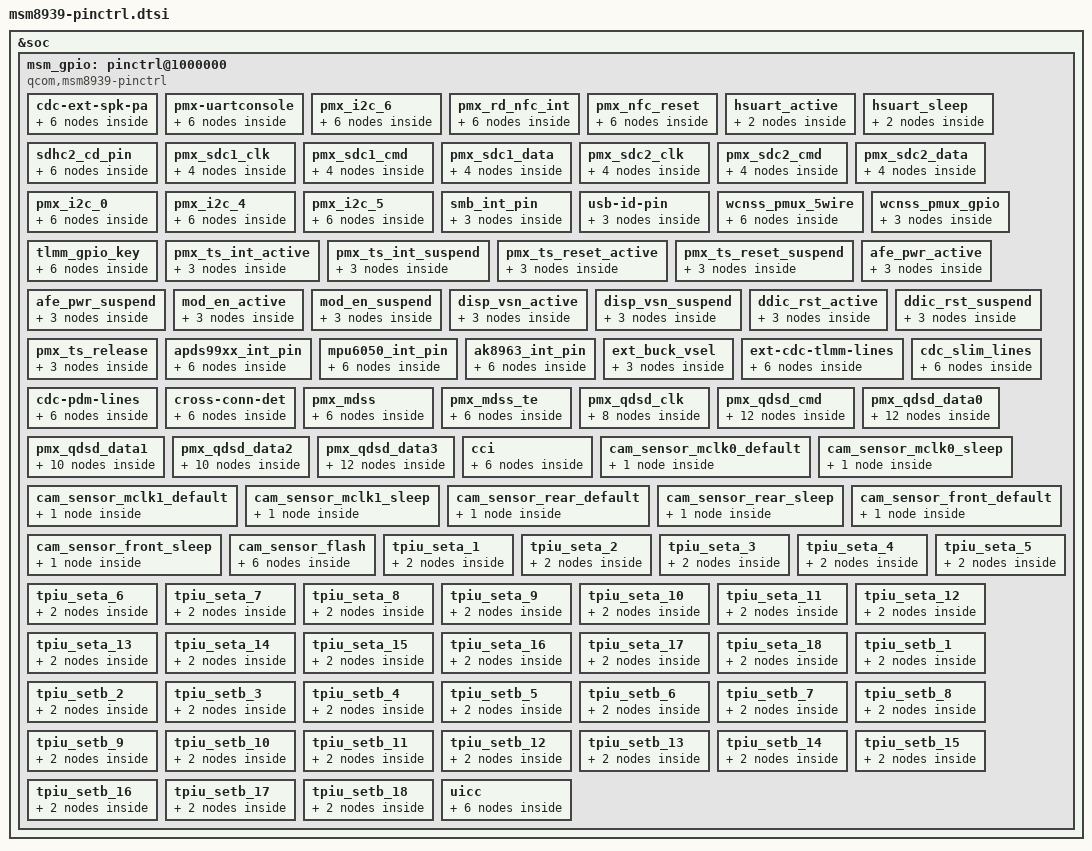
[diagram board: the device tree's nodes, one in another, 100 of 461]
/* Copyright (c) 2014-2015, The Linux Foundation. All rights reserved.
 * Copyright (c) 2018, Pavel Dubrova <pashadubrova@gmail.com
 *
 * This program is free software; you can redistribute it and/or modify
 * it under the terms of the GNU General Public License version 2 and
 * only version 2 as published by the Free Software Foundation.
 *
 * This program is distributed in the hope that it will be useful,
 * but WITHOUT ANY WARRANTY; without even the implied warranty of
 * MERCHANTABILITY or FITNESS FOR A PARTICULAR PURPOSE.  See the
 * GNU General Public License for more details.
 */

&soc {
	msm_gpio: pinctrl@1000000 {
		compatible = "qcom,msm8939-pinctrl";
		reg = <0x1000000 0x300000>;
		interrupts = <0 208 0>;
		gpio-controller;
		#gpio-cells = <2>;
		interrupt-controller;
		#interrupt-cells = <2>;

		cdc-ext-spk-pa {
			cdc_ext_spk_pa_active: cdc_ext_spk_pa_on {
				mux {
					pins = "gpio0";
					function = "gpio";
				};

				config {
					pins = "gpio0";
					drive-strength = <8>;
					output-low;
					bias-pull-none;
				};
			};

			cdc_ext_spk_pa_sus: cdc_ext_spk_pa_off {
				mux {
					pins = "gpio0";
					function = "gpio";
				};

				config {
					pins = "gpio0";
					drive-strength = <2>;
					bias-disable;
				};
			};
		};

		pmx-uartconsole {
			uart_console_active: uart_console_active {
				mux {
					pins = "gpio4", "gpio5";
					function = "gpio";
				};

				config {
					pins = "gpio4", "gpio5";
					drive-strength = <2>;
					bias-disable;
				};
			};

			uart_console_sleep: uart_console_sleep {
				mux {
					pins = "gpio4", "gpio5";
					function = "blsp_uart2";
				};

				config {
					pins = "gpio4", "gpio5";
					drive-strength = <2>;
					bias-pull-down;
				};
			};
		};

		pmx_i2c_6 {
			/* active state */
			i2c_6_active: i2c_6_active {
				mux {
					/* CLK, DATA */
					pins = "gpio22", "gpio23";
					function = "blsp_i2c6";
				};

				config {
					pins = "gpio22", "gpio23";
					drive-strength = <2>; /* 2 MA */
					bias-disable; /* No PULL */
				};
			};

			/* suspended state */
			i2c_6_sleep: i2c_6_sleep {
				mux {
					/* CLK, DATA */
					pins = "gpio22", "gpio23";
					function = "blsp_i2c6";
				};

				config {
					pins = "gpio22", "gpio23";
					drive-strength = <2>; /* 2 MA */
					bias-disable; /* No PULL */
				};
			};
		};

		pmx_rd_nfc_int {
			nfc_int_active: nfc_int_active {
				mux {
					pins = "gpio21";
					function = "gpio";
				};

				config {
					pins = "gpio21";
					drive-strength = <6>;
					bias-pull-up;
				};
			};

			nfc_int_suspend: nfc_int_suspend {
				mux {
					pins = "gpio21";
					function = "gpio";
				};

				config {
					pins = "gpio21";
					drive-strength = <6>;
					bias-pull-up;
				};
			};
		};

		pmx_nfc_reset {
			nfc_disable_active: nfc_disable_active {
				mux {
					pins = "gpio20";
					function = "gpio";
				};

				config {
					pins = "gpio20";
					drive-strength = <6>;
					bias-pull-up;
				};
			};

			nfc_disable_suspend: nfc_disable_suspend {
				mux {
					pins = "gpio20";
					function = "gpio";
				};

				config {
					pins = "gpio20";
					drive-strength = <6>;
					bias-disable;
				};
			};
		};

		hsuart_active: hsuart_active {
			mux {
				pins = "gpio0", "gpio1", "gpio2", "gpio3";
				function = "blsp_uart1";
			};

			config {
				pins = "gpio0", "gpio1", "gpio2", "gpio3";
				drive-strength = <16>;
				bias-disable;
			};
		};

		hsuart_sleep: hsuart_sleep {
			mux {
				pins = "gpio0", "gpio1", "gpio2", "gpio3";
				function = "blsp_uart1";
			};

			config {
				pins = "gpio0", "gpio1", "gpio2", "gpio3";
				drive-strength = <2>;
				bias-disable;
			};
		};

		sdhc2_cd_pin {
			sdc2_cd_on: cd_on {
				mux {
					pins = "gpio38";
					function = "gpio";
				};

				config {
					pins = "gpio38";
					drive-strength = <2>;
					bias-pull-up;
				};
			};

			sdc2_cd_off: cd_off {
				mux {
					pins = "gpio38";
					function = "gpio";
				};

				config {
					pins = "gpio38";
					drive-strength = <2>;
					bias-disable;
				};
			};
		};

		pmx_sdc1_clk {
			sdc1_clk_on: clk_on {
				config {
					pins = "sdc1_clk";
					bias-disable; /* NO pull */
					drive-strength = <16>; /* 16 MA */
				};
			};

			sdc1_clk_off: clk_off {
				config {
					pins = "sdc1_clk";
					bias-disable; /* NO pull */
					drive-strength = <2>; /* 2 MA */
				};
			};
		};

		pmx_sdc1_cmd {
			sdc1_cmd_on: cmd_on {
				config {
					pins = "sdc1_cmd";
					bias-pull-up; /* pull up */
					drive-strength = <10>; /* 10 MA */
				};
			};

			sdc1_cmd_off: cmd_off {
				config {
					pins = "sdc1_cmd";
					bias-pull-up; /* pull up */
					drive-strength = <2>; /* 2 MA */
				};
			};
		};

		pmx_sdc1_data {
			sdc1_data_on: data_on {
				config {
					pins = "sdc1_data";
					bias-pull-up; /* pull up */
					drive-strength = <10>; /* 10 MA */
				};
			};

			sdc1_data_off: data_off {
				config {
					pins = "sdc1_data";
					bias-pull-up; /* pull up */
					drive-strength = <2>; /* 2 MA */
				};
			};
		};

		pmx_sdc2_clk {
			sdc2_clk_on: clk_on {
				config {
					pins = "sdc2_clk";
					bias-disable; /* NO pull */
					drive-strength = <16>; /* 16 MA */
				};
			};

			sdc2_clk_off: clk_off {
				config {
					pins = "sdc2_clk";
					bias-disable; /* NO pull */
					drive-strength = <2>; /* 2 MA */
				};
			};
		};

		pmx_sdc2_cmd {
			sdc2_cmd_on: cmd_on {
				config {
					pins = "sdc2_cmd";
					bias-pull-up; /* pull up */
					drive-strength = <10>; /* 10 MA */
				};
			};

			sdc2_cmd_off: cmd_off {
				config {
					pins = "sdc2_cmd";
					bias-pull-up; /* pull up */
					drive-strength = <2>; /* 2 MA */
				};
			};
		};

		pmx_sdc2_data {
			sdc2_data_on: data_on {
				config {
					pins = "sdc2_data";
					bias-pull-up; /* pull up */
					drive-strength = <10>; /* 10 MA */
				};
			};

			sdc2_data_off: data_off {
				config {
					pins = "sdc2_data";
					bias-pull-up; /* pull up */
					drive-strength = <2>; /* 2 MA */
				};
			};
		};

		pmx_i2c_0 {
			i2c_0_active: i2c_0_active {
				mux {
					pins = "gpio6", "gpio7";
					function = "blsp_i2c2";
				};

				config {
					pins = "gpio6", "gpio7";
					drive-strength = <2>; /* 2 MA */
					bias-disable;         /* No PULL */
				};
			};

			i2c_0_sleep: i2c_0_sleep {
				mux {
					pins = "gpio6", "gpio7";
					function = "blsp_i2c2";
				};

				config {
					pins = "gpio6", "gpio7";
					drive-strength = <2>; /* 2 MA */
					bias-disable;	      /* No PULL */
				};
			};
		};

		pmx_i2c_4 {
			i2c_4_active: i2c_4_active {
				mux {
					pins = "gpio14", "gpio15";
					function = "blsp_i2c4";
				};

				config {
					pins = "gpio14", "gpio15";
					drive-strength = <2>; /* 2 MA */
					bias-disable;         /* No PULL */
				};
			};

			i2c_4_sleep: i2c_4_sleep {
				mux {
					pins = "gpio14", "gpio15";
					function = "blsp_i2c4";
				};

				config {
					pins = "gpio14", "gpio15";
					drive-strength = <2>; /* 2 MA */
					bias-disable;	      /* No PULL */
				};
			};
		};

		pmx_i2c_5 {
			i2c_5_active: i2c_5_active {
				mux {
					pins = "gpio18", "gpio19";
					function = "blsp_i2c5";
				};

				config {
					pins = "gpio18", "gpio19";
					drive-strength = <2>; /* 2 MA */
					bias-disable;         /* No PULL */
				};
			};

			i2c_5_sleep: i2c_5_sleep {
				mux {
					pins = "gpio18", "gpio19";
					function = "blsp_i2c5";
				};

				config {
					pins = "gpio18", "gpio19";
					drive-strength = <2>; /* 2 MA */
					bias-disable;	      /* No PULL */
				};
			};
		};

		smb_int_pin {
			smb_int_default: smb_int_default {
				mux {
					pins = "gpio62";
					function = "gpio";
				};

				config {
					pins = "gpio62";
					drive-strength = <2>;	/* 2 MA */
					bias-pull-up;		/* PULL UP*/
				};
			};
		};

		usb-id-pin {
			usbid_default: default {
				mux {
					pins = "gpio110";
					function = "gpio";
				};

				config {
					pins = "gpio110";
					drive-strength = <8>;
					bias-pull-up;
				};
			};
		};

#if 0
		 spi0_active {
                        /* MOSI, MISO, CLK */
                        qcom,pins = <&gp 8>, <&gp 9>, <&gp 11>;
                        qcom,num-grp-pins = <3>;
                        qcom,pin-func = <1>;
                        label = "spi0-active";
                        /* active state */
                        spi0_default: spi0_default {
                             wcnss_pmux_5wire   drive-strength = <12>; /* 12 MA */
                                bias-disable = <0>; /* No PULL */
                        };
                };

                spi0_suspend {
                        /* MOSI, MISO, CLK */
                        qcom,pins = <&gp 8>, <&gp 9>, <&gp 11>;
                        qcom,num-grp-pins = <3>;
                        qcom,pin-func = <0>;
                        label = "spi0-suspend";
                        /* suspended state */
                        spi0_sleep: spi0_sleep {
                                drive-strength = <2>; /* 2 MA */
			        bias-pull-down; /* PULL Down */
                        };
                };

                spi0_cs0_active {
                        /* CS */
                        qcom,pins = <&gp 10>;
                        qcom,num-grp-pins = <1>;
                        qcom,pin-func = <1>;
                        label = "spi0-cs0-active";
                        spi0_cs0_active: cs0_active {
                                drive-strength = <2>;
                                bias-disable = <0>;
                        };
                };

                spi0_cs0_suspend {
                        /* CS */
                        qcom,pins = <&gp 10>;
                        qcom,num-grp-pins = <1>;
                        qcom,pin-func = <0>;
                        label = "spi0-cs0-suspend";
                        spi0_cs0_sleep: cs0_sleep {
                                drive-strength = <2>;
                                bias-disable = <0>;
                        };
                };

		spi5_active {
                        /* MOSI, MISO, CLK */
                        qcom,pins = <&gp 16>, <&gp 17>, <&gp 19>;
                        qcom,num-grp-pins = <3>;
                        qcom,pin-func = <1>;
                        label = "spi5-active";
                        /* active state */
                        spi5_default: spi5_default {
                                drive-strength = <16>; /* 16 MA */
                                bias-disable = <0>; /* No PULL */
                        };
                };

                spi5_suspend {
                        /* MOSI, MISO, CLK */
                        qcom,pins = <&gp 16>, <&gp 17>, <&gp 19>;
                        qcom,num-grp-pins = <3>;
                        qcom,pin-func = <0>;
                        label = "spi5-suspend";
                        /* suspended state */
                        spi5_sleep: spi5_sleep {
                                drive-strength = <2>; /* 2 MA */
                                bias-disable = <0>; /* No PULL */
                        };
                };

                spi5_cs0_active {
                        /* CS */
                        qcom,pins = <&gp 18>;
                        qcom,num-grp-pins = <1>;
                        qcom,pin-func = <1>;
                        label = "spi5-cs0-active";
                        spi5_cs0_active: cs0_active {
                                drive-strength = <2>;
                                bias-disable = <0>;
                        };
                };

                spi5_cs0_suspend {
                        /* CS */
                        qcom,pins = <&gp 18>;
                        qcom,num-grp-pins = <1>;
                        qcom,pin-func = <0>;
                        label = "spi5-cs0-suspend";
                        spi5_cs0_sleep: cs0_sleep {
                                drive-strength = <2>;
                                bias-disable = <0>;
                        };
                };
#endif

		wcnss_pmux_5wire {
			wcnss_default: wcnss_default {
				mux {
					pins = "gpio40", "gpio41",
						"gpio42", "gpio43",
						"gpio44";
					function = "wcss_wlan";
				};

				config {
					pins = "gpio40", "gpio41",
						"gpio42", "gpio43",
						"gpio44";
					drive-strength = <6>; /* 6 MA */
					bias-pull-up; /* PULL UP */
				};
			};

			wcnss_sleep: wcnss_sleep {
				mux {
					pins = "gpio40", "gpio41",
						"gpio42", "gpio43",
						"gpio44";
					function = "wcss_wlan";
				};

				config {
					pins = "gpio40", "gpio41",
						"gpio42", "gpio43",
						"gpio44";
					drive-strength = <2>; /* 2 MA */
					bias-pull-down; /* PULL Down */
				};
			};
		};

		wcnss_pmux_gpio: wcnss_pmux_gpio {
			wcnss_gpio_default: wcnss_gpio_default {
				mux {
					pins = "gpio40", "gpio41",
						"gpio42", "gpio43",
						"gpio44";
					function = "gpio";
				};

				config {
					pins = "gpio40", "gpio41",
						"gpio42", "gpio43",
						"gpio44";
					drive-strength = <6>; /* 6 MA */
					bias-pull-up; /* PULL UP */
				};
			};
		};

		tlmm_gpio_key {
			gpio_key_active: gpio_key_active {
				mux {
					pins = "gpio107", "gpio108", "gpio109";
					function = "gpio";
				};

				config {
					pins = "gpio107", "gpio108", "gpio109";
					drive-strength = <2>;
					bias-pull-up;
				};
			};

			gpio_key_suspend: gpio_key_suspend {
				mux {
					pins = "gpio107", "gpio108", "gpio109";
					function = "gpio";
				};

				config {
					pins = "gpio107", "gpio108", "gpio109";
					drive-strength = <2>;
					bias-pull-up;
				};
			};
		};

		/* add pingrp for touchscreen */
		pmx_ts_int_active {
			ts_int_active: ts_int_active {
				mux {
					pins = "gpio13";
					function = "gpio";
				};

				config {
					pins = "gpio13";
					drive-strength = <16>;
					bias-pull-up;
				};
			};
		};

		pmx_ts_int_suspend {
			ts_int_suspend: ts_int_suspend {
				mux {
					pins = "gpio13";
					function = "gpio";
				};

				config {
					pins = "gpio13";
					drive-strength = <2>;
					bias-pull-down;
				};
			};
		};

		pmx_ts_reset_active {
			ts_reset_active: ts_reset_active {
				mux {
					pins = "gpio12";
					function = "gpio";
				};

				config {
					pins = "gpio12";
					drive-strength = <16>;
					bias-pull-up;
				};
			};
		};

		pmx_ts_reset_suspend {
			ts_reset_suspend: ts_reset_suspend {
				mux {
					pins = "gpio12";
					function = "gpio";
				};

				config {
					pins = "gpio12";
					drive-strength = <2>;
				bias-pull-down;
				};
			};
		};


		afe_pwr_active {
			afe_pwr_active: afe_pwr_active {
				mux {
					pins = "gpio75";
					function = "gpio";
				};

				config {
					pins = "gpio75";
					drive-strength = <16>;
					output-high;
				};
			};
		};


		afe_pwr_suspend {
			afe_pwr_suspend: afe_pwr_suspend {
				mux {
					pins = "gpio75";
					function = "gpio";
				};

				config {
					pins = "gpio75";
					drive-strength = <2>;
					output-low;
				};
			};
		};

		mod_en_active {
			mod_en_active: mod_en_active {
				mux {
					pins = "gpio97";
					function = "gpio";
				};

				config {
					pins = "gpio97";
					drive-strength = <16>;
					output-high;
				};
			};
		};

		mod_en_suspend {
			mod_en_suspend: mod_en_suspend {
				mux {
					pins = "gpio97";
					function = "gpio";
				};

				config {
					pins = "gpio97";
					drive-strength = <2>;
					output-low;
				};
			};
		};

		disp_vsn_active {
			disp_vsn_active: disp_vsn_active {
				mux {
					pins = "gpio77";
					function = "gpio";
				};

				config {
					pins = "gpio77";
					drive-strength = <16>;
					output-high;
				};
			};
		};

		disp_vsn_suspend {
			disp_vsn_suspend: disp_vsn_suspend {
				mux {
					pins = "gpio77";
					function = "gpio";
				};

				config {
					pins = "gpio77";
					drive-strength = <2>;
					output-low;
				};
			};
		};

		ddic_rst_active {
			ddic_rst_active: ddic_rst_active {
				mux {
					pins = "gpio25";
					function = "gpio";
				};

				config {
					pins = "gpio25";
					drive-strength = <16>;
					output-high;
				};
			};
		};

		ddic_rst_suspend {
			ddic_rst_suspend: ddic_rst_suspend {
				mux {
					pins = "gpio25";
					function = "gpio";
				};

				config {
					pins = "gpio25";
					drive-strength = <2>;
					output-low;
				};
			};
		};

		pmx_ts_release {
			ts_release: ts_release {
				mux {
					pins = "gpio12", "gpio13";
					function = "gpio";
				};

				config {
					pins = "gpio12", "gpio13";
					drive-strength = <2>;
					bias-pull-down;
				};
			};
		};

		/* Ambient light and proximity sensor apds9930 and apds9900 */
		apds99xx_int_pin {
			apds99xx_default: apds99xx_default {
				mux {
					pins = "gpio113";
					function = "gpio";
				};

				config {
					pins = "gpio113";
					drive-strength = <6>;
					bias-pull-up;
				};
			};

			apds99xx_sleep: apds99xx_sleep {
				mux {
					pins = "gpio113";
					function = "gpio";
				};

				config {
					pins = "gpio113";
					drive-strength = <2>;
					bias-pull-down;
				};
			};
		};

		/* Gyroscope and accelerometer sensor combo */
		mpu6050_int_pin {
			mpu6050_default: mpu6050_default {
				mux {
					pins = "gpio115";
					function = "gpio";
				};

				config {
					pins = "gpio115";
					drive-strength = <6>;
					bias-pull-up;
				};
			};

			mpu6050_sleep: mpu6050_sleep {
				mux {
					pins = "gpio115";
					function = "gpio";
				};

				config {
					pins = "gpio115";
					drive-strength = <2>;
					bias-pull-down;
				};
			};
		};

		ak8963_int_pin {
			ak8963_default: ak8963_default {
				mux {
					pins = "gpio69";
					function = "gpio";
				};

				config {
					pins = "gpio69";
					drive-strength = <6>;
					bias-pull-up;
				};
			};

			ak8963_sleep: ak8963_sleep {
				mux {
					pins = "gpio69";
					function = "gpio";
				};

				config {
					pins = "gpio69";
					drive-strength = <2>;
					bias-pull-down;
				};
			};
		};

		ext_buck_vsel {
			ext_buck_vsel_default: vsel0 {
				mux {
					pins = "gpio111";
					function = "gpio";
				};

				config {
					pins = "gpio111";
					drive-strength = <2>;
				};
			};
		};

		ext-cdc-tlmm-lines {
			ext_cdc_tlmm_lines_act: tlmm_lines_on {
				mux {
					pins = "gpio112", "gpio116",
						"gpio117", "gpio 118",
						"gpio119";
					function = "gpio";
				};

				config {
					pins = "gpio112", "gpio116",
						"gpio117", "gpio 118",
						"gpio119";
					drive-strength = <8>;
				};
			};

			ext_cdc_tlmm_lines_sus: tlmm_lines_off {
				mux {
					pins = "gpio112", "gpio116",
						"gpio117", "gpio 118",
						"gpio119";
					function = "gpio";
				};

				config {
					pins = "gpio112", "gpio116",
						"gpio117", "gpio 118",
						"gpio119";
					drive-strength = <2>;
					bias-disable;
				};
			};
		};

		cdc_slim_lines {
			cdc_slim_lines_act: slim_lines_on {
				mux {
					pins = "gpio63";
					function = "gpio";
				};

				cconfig {
					pins = "gpio63";
					drive-strength = <8>;
					bias-pull-none;
					output-high;
				};
			};

			cdc_slim_lines_sus: slim_lines_off {
				mux {
					pins = "gpio63";
					function = "gpio";
				};

				cconfig {
					pins = "gpio63";
					drive-strength = <2>;
					bias-disable;
				};
			};
		};

		cdc-pdm-lines {
			cdc_pdm_lines_act: pdm_lines_on {
				mux {
					pins = "gpio63", "gpio64",
						"gpio65", "gpio66",
						"gpio67", "gpio68";
					function = "gpio";
				};

				config {
					pins = "gpio63", "gpio64",
						"gpio65", "gpio66",
						"gpio67", "gpio68";
					drive-strength = <8>;
					bias-pull-none;
				};
			};

			cdc_pdm_lines_sus: pdm_lines_off {
				mux {
					pins = "gpio63", "gpio64",
						"gpio65", "gpio66",
						"gpio67", "gpio68";
					function = "gpio";
				};

				config {
					pins = "gpio63", "gpio64",
						"gpio65", "gpio66",
						"gpio67", "gpio68";
					drive-strength = <2>;
					bias-pull-down;
				};
			};
		};

		cross-conn-det {
			cross_conn_det_act: lines_on {
				mux {
					pins = "gpio120";
					function = "gpio";
				};

				config {
					pins = "gpio120";
					drive-strength = <8>;
					output-low;
					bias-pull-down;
				};
			};

			cross_conn_det_sus: lines_off {
				mux {
					pins = "gpio120";
					function = "gpio";
				};

				config {
					pins = "gpio120";
					drive-strength = <2>;
					bias-disable;
				};
			};
		};

		pmx_mdss {
			mdss_dsi_active: mdss_dsi_active {
				mux {
					function = "gpio";
				};

				config {
					drive-strength = <8>; /* 8 mA */
					bias-disable = <0>; /* no pull */
				};
			};

			mdss_dsi_suspend: mdss_dsi_suspend {
				mux {
					function = "gpio";
				};

				config {
					drive-strength = <2>; /* 2 mA */
					bias-pull-down; /* pull down */
				};
			};
		};

		pmx_mdss_te {
			mdss_te_active: mdss_te_active {
				mux {
					function = "gpio";
				};

				config {
					drive-strength = <2>; /* 2 mA */
					bias-pull-down; /* pull down */
				};
			};

			mdss_te_suspend: mdss_te_suspend {
				mux {
					function = "gpio";
				};

				config {
					drive-strength = <2>; /* 2 mA */
					bias-pull-down; /* pull down */
				};
			};
		};

		pmx_qdsd_clk {
			qdsd_clk_sdcard: clk_sdcard {
				config {
					pins = "qdsd_clk";
					bias-disable; /* NO pull */
					drive-strength = <7>; /* 7 MA */
				};
			};

			qdsd_clk_trace: clk_trace {
				config {
					pins = "qdsd_clk";
					bias-pull-down; /* pull down */
					drive-strength = <0>; /* 0 MA */
				};
			};

			qdsd_clk_swdtrc: clk_swdtrc {
				config {
					pins = "qdsd_clk";
					bias-pull-down; /* pull down */
					drive-strength = <0>; /* 0 MA */
				};
			};

			qdsd_clk_spmi: clk_spmi {
				config {
					pins = "qdsd_clk";
					bias-pull-down; /* pull down */
					drive-strength = <0>; /* 0 MA */
				};
			};
		};

		pmx_qdsd_cmd {
			qdsd_cmd_sdcard: cmd_sdcard {
				config {
					pins = "qdsd_cmd";
					bias-pull-down; /* pull down */
					drive-strength = <3>; /* 3 MA */
				};
			};

			qdsd_cmd_trace: cmd_trace {
				config {
					pins = "qdsd_cmd";
					bias-pull-down; /* pull down */
					drive-strength = <0>; /* 0 MA */
				};
			};

			qdsd_cmd_swduart: cmd_uart {
				config {
					pins = "qdsd_cmd";
					bias-pull-up; /* pull up */
					drive-strength = <0>; /* 0 MA */
				};
			};

			qdsd_cmd_swdtrc: cmd_swdtrc {
				config {
					pins = "qdsd_cmd";
					bias-pull-up; /* pull up */
					drive-strength = <0>; /* 0 MA */
				};
			};

			qdsd_cmd_jtag: cmd_jtag {
				config {
					pins = "qdsd_cmd";
					bias-disable; /* NO pull */
					drive-strength = <3>; /* 3 MA */
				};
			};

			qdsd_cmd_spmi: cmd_spmi {
				config {
					pins = "qdsd_cmd";
					bias-pull-down; /* pull down */
					drive-strength = <4>; /* 4 MA */
				};
			};
		};

		pmx_qdsd_data0 {
			qdsd_data0_sdcard: data0_sdcard {
				config {
					pins = "qdsd_data0";
					bias-pull-down; /* pull down */
					drive-strength = <3>; /* 3 MA */
				};
			};

			qdsd_data0_trace: data0_trace {
				config {
					pins = "qdsd_data0";
					bias-pull-down; /* pull down */
					drive-strength = <0>; /* 0 MA */
				};
			};

			qdsd_data0_swduart: data0_uart {
				config {
					pins = "qdsd_data0";
					bias-pull-down; /* pull down */
					drive-strength = <0>; /* 0 MA */
				};
			};

			qdsd_data0_swdtrc: data0_swdtrc {
				config {
					pins = "qdsd_data0";
					bias-pull-down; /* pull down */
					drive-strength = <0>; /* 0 MA */
				};
			};

			qdsd_data0_jtag: data0_jtag {
				config {
					pins = "qdsd_data0";
					bias-pull-up; /* pull up */
					drive-strength = <0>; /* 0 MA */
				};
			};

			qdsd_data0_spmi: data0_spmi {
				config {
					pins = "qdsd_data0";
					bias-pull-down; /* pull down */
					drive-strength = <0>; /* 0 MA */
				};
			};
		};

		pmx_qdsd_data1 {
			qdsd_data1_sdcard: data1_sdcard {
				config {
					pins = "qdsd_data1";
					bias-pull-down; /* pull down */
					drive-strength = <3>; /* 3 MA */
				};
			};

			qdsd_data1_trace: data1_trace {
				config {
					pins = "qdsd_data1";
					bias-pull-down; /* pull down */
					drive-strength = <0>; /* 0 MA */
				};
			};

			qdsd_data1_swduart: data1_uart {
				config {
					pins = "qdsd_data1";
					bias-pull-down; /* pull down */
					drive-strength = <0>; /* 0 MA */
				};
			};

			qdsd_data1_swdtrc: data1_swdtrc {
				config {
					pins = "qdsd_data1";
					bias-pull-down; /* pull down */
					drive-strength = <0>; /* 0 MA */
				};
			};

			qdsd_data1_jtag: data1_jtag {
				config {
					pins = "qdsd_data1";
					bias-pull-down; /* pull down */
					drive-strength = <0>; /* 0 MA */
				};
			};
		};

		pmx_qdsd_data2 {
			qdsd_data2_sdcard: data2_sdcard {
				config {
					pins = "qdsd_data2";
					bias-pull-down; /* pull down */
					drive-strength = <3>; /* 3 MA */
				};
			};

			qdsd_data2_trace: data2_trace {
				config {
					pins = "qdsd_data2";
					bias-pull-down; /* pull down */
					drive-strength = <0>; /* 0 MA */
				};
			};

			qdsd_data2_swduart: data2_uart {
				config {
					pins = "qdsd_data2";
					bias-pull-down; /* pull down */
					drive-strength = <0>; /* 0 MA */
				};
			};

			qdsd_data2_swdtrc: data2_swdtrc {
				config {
					pins = "qdsd_data2";
					bias-pull-down; /* pull down */
					drive-strength = <0>; /* 0 MA */
				};
			};

			qdsd_data2_jtag: data2_jtag {
				config {
					pins = "qdsd_data2";
					bias-pull-up; /* pull up */
					drive-strength = <3>; /* 3 MA */
				};
			};
		};

		pmx_qdsd_data3 {
			qdsd_data3_sdcard: data3_sdcard {
				config {
					pins = "qdsd_data3";
					bias-pull-down; /* pull down */
					drive-strength = <3>; /* 3 MA */
				};
			};

			qdsd_data3_trace: data3_trace {
				config {
					pins = "qdsd_data3";
					bias-pull-down; /* pull down */
					drive-strength = <0>; /* 0 MA */
				};
			};

			qdsd_data3_swduart: data3_uart {
				config {
					pins = "qdsd_data3";
					bias-pull-up; /* pull up */
					drive-strength = <0>; /* 0 MA */
				};
			};

			qdsd_data3_swdtrc: data3_swdtrc {
				config {
					pins = "qdsd_data3";
					bias-pull-up; /* pull up */
					drive-strength = <0>; /* 0 MA */
				};
			};

			qdsd_data3_jtag: data3_jtag {
				config {
					pins = "qdsd_data3";
					bias-pull-up; /* pull up */
					drive-strength = <0>; /* 0 MA */
				};
			};

			qdsd_data3_spmi: data3_spmi {
				config {
					pins = "qdsd_data3";
					bias-pull-down; /* pull down */
					drive-strength = <3>; /* 3 MA */
				};
			};
		};

		cci {
			/* active state */
			cci0_default: cci0_default {
				/* CLK, DATA */
				mux {
					pins = "gpio29", "gpio30";
					function = "cci_i2c";
				};

				config {
					pins = "gpio29", "gpio30";
					drive-strength = <2>; /* 2 MA */
					bias-disable = <0>; /* No PULL */
				};
			};

			/*suspended state */
			cci0_sleep: cci0_sleep {
				/* CLK, DATA */
				mux {
					pins = "gpio29", "gpio30";
					function = "cci_i2c";
				};

				config {
					pins = "gpio29", "gpio30";
					drive-strength = <2>; /* 2 MA */
					bias-disable = <0>; /* No PULL */
				};
			};
		};

		cam_sensor_mclk0_default: cam_sensor_mclk0_default {
			/* active state */
			cam_sensor_mclk0_default {
				/* MCLK */
				pins = "gpio26";
				function = "cam_mclk";
				drive-strength = <2>; /* 2 MA */
				bias-disable = <0>; /* No PULL */
			};
		};

		cam_sensor_mclk0_sleep: cam_sensor_mclk0_sleep {
			/*suspend state */
			cam_sensor_mclk0_sleep {
				/* MCLK */
				pins = "gpio26";
				function = "cam_mclk";
				drive-strength = <2>; /* 2 MA */
				bias-pull-down; /* PULL DOWN */
			};
		};

		cam_sensor_mclk1_default: cam_sensor_mclk1_default {
			/* active state */
			cam_sensor_mclk1_default {
				/* MCLK */
				pins = "gpio27";
				function = "cam_mclk";
				drive-strength = <2>; /* 2 MA */
				bias-disable = <0>; /* No PULL */
			};
		};

		cam_sensor_mclk1_sleep: cam_sensor_mclk1_sleep {
			/*suspend state */
			cam_sensor_mclk1_sleep {
				/* MCLK */
				pins = "gpio27";
				function = "cam_mclk";
				drive-strength = <2>; /* 2 MA */
				bias-pull-down; /* PULL DOWN */
			};
		};

		cam_sensor_rear_default: cam_sensor_rear_default {
			/* active state */
			cam_sensor_rear_default {
				/* RESET, STANDBY */
				pins = "gpio34", "gpio35";
				drive-strength = <2>; /* 2 MA */
				bias-disable = <0>; /* No PULL */
			};
		};

		cam_sensor_rear_sleep: cam_sensor_rear_sleep {
			/* suspend state */
			cam_sensor_rear_sleep {
				/* RESET, STANDBY */
				pins = "gpio34", "gpio35";
				drive-strength = <2>; /* 2 MA */
				bias-pull-down; /* PULL DOWN */
			};
		};

		cam_sensor_front_default: cam_sensor_front_default {
			/* active state */
			cam_sensor_front_default {
				/* RESET, STANDBY */
				pins = "gpio28", "gpio33";
				drive-strength = <2>; /* 2 MA */
				bias-disable = <0>; /* No PULL */
			};
		};

		cam_sensor_front_sleep: cam_sensor_front_sleep {
			/* suspend state */
			cam_sensor_front_sleep {
				/* RESET, STANDBY */
				pins = "gpio28", "gpio33";
				drive-strength = <2>; /* 2 MA */
				bias-pull-down = <0>; /* PULL DOWN */
			};
		};

		cam_sensor_flash {
			cam_sensor_flash_default: default {
				/* FLSH_RESET,FLASH_EN,FLASH_NOW */
				mux {
					pins = "gpio36", "gpio31","gpio32";
					function = "gpio";
				};

				config {
					pins = "gpio36", "gpio31","gpio32";
					bias-disable; /* NO PULL */
					drive-strength = <2>; /* 2 MA */
				};
			};

			cam_sensor_flash_sleep: sleep {
				mux {
					pins = "gpio36", "gpio31","gpio32";
					function = "gpio";
				};

				config {
					pins = "gpio36", "gpio31","gpio32";
					bias-pull-down; /* PULL DOWN */
					drive-strength = <2>; /* 2 MA */
				};
			};
		};

		/* CoreSight */
		tpiu_seta_1 {
			mux {
				pins = "gpio8";
				function = "qdss_traceclk_a";
			};

			config {
				pins = "gpio8";
				drive-strength = <16>;
				bias-disable;
			};
		};

		tpiu_seta_2 {
			mux {
				pins = "gpio9";
				function = "qdss_traceclk_a";
			};

			config {
				pins = "gpio9";
				drive-strength = <16>;
				bias-disable;
			};
		};

		tpiu_seta_3 {
			mux {
				pins = "gpio10";
				function = "qdss_traceclk_a";
			};

			config {
				pins = "gpio10";
				drive-strength = <16>;
				bias-disable;
			};
		};

		tpiu_seta_4 {
			mux {
				pins = "gpio39";
				function = "qdss_traceclk_a";
			};

			config {
				pins = "gpio39";
				drive-strength = <16>;
				bias-disable;
			};
		};

		tpiu_seta_5 {
			mux {
				pins = "gpio40";
				function = "qdss_traceclk_a";
			};

			config {
				pins = "gpio40";
				drive-strength = <16>;
				bias-disable;
			};
		};

		tpiu_seta_6 {
			mux {
				pins = "gpio41";
				function = "qdss_traceclk_a";
			};

			config {
				pins = "gpio41";
				drive-strength = <16>;
				bias-disable;
			};
		};

		tpiu_seta_7 {
			mux {
				pins = "gpio42";
				function = "qdss_traceclk_a";
			};

			config {
				pins = "gpio42";
				drive-strength = <16>;
				bias-disable;
			};
		};

		tpiu_seta_8 {
			mux {
				pins = "gpio43";
				function = "qdss_traceclk_a";
			};

			config {
				pins = "gpio43";
				drive-strength = <16>;
				bias-disable;
			};
		};

		tpiu_seta_9 {
			mux {
				pins = "gpio45";
				function = "qdss_traceclk_a";
			};

			config {
				pins = "gpio45";
				drive-strength = <16>;
				bias-disable;
			};
		};

		tpiu_seta_10 {
			mux {
				pins = "gpio46";
				function = "qdss_traceclk_a";
			};

			config {
				pins = "gpio46";
				drive-strength = <16>;
				bias-disable;
			};
		};

		tpiu_seta_11 {
			mux {
				pins = "gpio47";
				function = "qdss_traceclk_a";
			};

			config {
				pins = "gpio47";
				drive-strength = <16>;
				bias-disable;
			};
		};

		tpiu_seta_12 {
			mux {
				pins = "gpio48";
				function = "qdss_traceclk_a";
			};

			config {
				pins = "gpio48";
				drive-strength = <16>;
				bias-disable;
			};
		};

		tpiu_seta_13 {
			mux {
				pins = "gpio62";
				function = "qdss_traceclk_a";
			};

			config {
				pins = "gpio62";
				drive-strength = <16>;
				bias-disable;
			};
		};

		tpiu_seta_14 {
			mux {
				pins = "gpio69";
				function = "qdss_traceclk_a";
			};

			config {
				pins = "gpio69";
				drive-strength = <16>;
				bias-disable;
			};
		};

		tpiu_seta_15 {
			mux {
				pins = "gpio112";
				function = "qdss_traceclk_a";
			};

			config {
				pins = "gpio112";
				drive-strength = <16>;
				bias-disable;
			};
		};

		tpiu_seta_16 {
			mux {
				pins = "gpio113";
				function = "qdss_traceclk_a";
			};

			config {
				pins = "gpio113";
				drive-strength = <16>;
				bias-disable;
			};
		};

		tpiu_seta_17 {
			mux {
				pins = "gpio114";
				function = "qdss_traceclk_a";
			};

			config {
				pins = "gpio114";
				drive-strength = <16>;
				bias-disable;
			};
		};

		tpiu_seta_18 {
			mux {
				pins = "gpio115";
				function = "qdss_traceclk_a";
			};

			config {
				pins = "gpio115";
				drive-strength = <16>;
				bias-disable;
			};
		};

		tpiu_setb_1 {
			mux {
				pins = "gpio4";
				function = "qdss_traceclk_b";
			};

			config {
				pins = "gpio4";
				drive-strength = <16>;
				bias-disable;
			};
		};

		tpiu_setb_2 {
			mux {
				pins = "gpio5";
				function = "qdss_traceclk_b";
			};

			config {
				pins = "gpio5";
				drive-strength = <16>;
				bias-disable;
			};
		};

		tpiu_setb_3 {
			mux {
				pins = "gpio26";
				function = "qdss_traceclk_b";
			};

			config {
				pins = "gpio26";
				drive-strength = <16>;
				bias-disable;
			};
		};

		tpiu_setb_4 {
			mux {
				pins = "gpio27";
				function = "qdss_traceclk_b";
			};

			config {
				pins = "gpio27";
				drive-strength = <16>;
				bias-disable;
			};
		};

		tpiu_setb_5 {
			mux {
				pins = "gpio28";
				function = "qdss_traceclk_b";
			};

			config {
				pins = "gpio28";
				drive-strength = <16>;
				bias-disable;
			};
		};

		tpiu_setb_6 {
			mux {
				pins = "gpio29";
				function = "qdss_traceclk_b";
			};

			config {
				pins = "gpio29";
				drive-strength = <16>;
				bias-disable;
			};
		};

		tpiu_setb_7 {
			mux {
				pins = "gpio30";
				function = "qdss_traceclk_b";
			};

			config {
				pins = "gpio30";
				drive-strength = <16>;
				bias-disable;
			};
		};

		tpiu_setb_8 {
			mux {
				pins = "gpio31";
				function = "qdss_traceclk_b";
			};

			config {
				pins = "gpio31";
				drive-strength = <16>;
				bias-disable;
			};
		};

		tpiu_setb_9 {
			mux {
				pins = "gpio32";
				function = "qdss_traceclk_b";
			};

			config {
				pins = "gpio32";
				drive-strength = <16>;
				bias-disable;
			};
		};

		tpiu_setb_10 {
			mux {
				pins = "gpio33";
				function = "qdss_traceclk_b";
			};

			config {
				pins = "gpio33";
				drive-strength = <16>;
				bias-disable;
			};
		};

		tpiu_setb_11 {
			mux {
				pins = "gpio34";
				function = "qdss_traceclk_b";
			};

			config {
				pins = "gpio34";
				drive-strength = <16>;
				bias-disable;
			};
		};

		tpiu_setb_12 {
			mux {
				pins = "gpio35";
				function = "qdss_traceclk_b";
			};

			config {
				pins = "gpio35";
				drive-strength = <16>;
				bias-disable;
			};
		};

		tpiu_setb_13 {
			mux {
				pins = "gpio36";
				function = "qdss_traceclk_b";
			};

			config {
				pins = "gpio36";
				drive-strength = <16>;
				bias-disable;
			};
		};

		tpiu_setb_14 {
			mux {
				pins = "gpio37";
				function = "qdss_traceclk_b";
			};

			config {
				pins = "gpio37";
				drive-strength = <16>;
				bias-disable;
			};
		};

		tpiu_setb_15 {
			mux {
				pins = "gpio110";
				function = "qdss_traceclk_b";
			};

			config {
				pins = "gpio110";
				drive-strength = <16>;
				bias-disable;
			};
		};

		tpiu_setb_16 {
			mux {
				pins = "gpio111";
				function = "qdss_traceclk_b";
			};

			config {
				pins = "gpio111";
				drive-strength = <16>;
				bias-disable;
			};
		};

		tpiu_setb_17 {
			mux {
				pins = "gpio120";
				function = "qdss_traceclk_b";
			};

			config {
				pins = "gpio120";
				drive-strength = <16>;
				bias-disable;
			};
		};

		tpiu_setb_18 {
			mux {
				pins = "gpio121";
				function = "qdss_traceclk_b";
			};

			config {
				pins = "gpio121";
				drive-strength = <16>;
				bias-disable;
			};
		};

		uicc {
			uicc_active: active {
				mux {
					pins = "gpio53", "gpio54";
					function = "gpio";
				};

				config {
					pins = "gpio53", "gpio54";
					drive-strength = <8>;
					bias-disable;
				};
			};

			uicc_sleep: sleep {
				mux {
					pins = "gpio53", "gpio54";
					function = "gpio";
				};

				config {
					pins = "gpio53", "gpio54";
					drive-strength = <2>;
					bias-pull-down;
				};
			};
		};
	};
};
